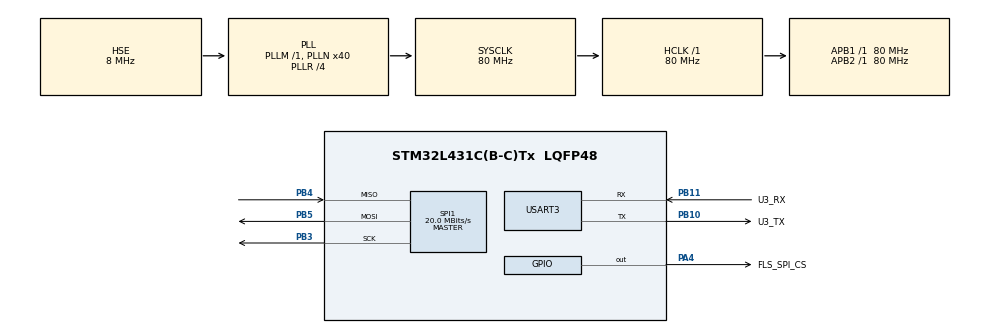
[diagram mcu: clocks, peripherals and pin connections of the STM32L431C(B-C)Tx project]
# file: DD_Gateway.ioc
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Mcu.Family=STM32L4
Mcu.Name=STM32L431C(B-C)Tx
Mcu.Package=LQFP48
NVIC.PriorityGroup=NVIC_PRIORITYGROUP_4
PA4.GPIO_Label=FLS_SPI_CS
PA4.Signal=GPIO_Output
PB10.GPIO_Label=U3_TX
PB10.Mode=Asynchronous
PB10.Signal=USART3_TX
PB11.GPIO_Label=U3_RX
PB11.Mode=Asynchronous
PB11.Signal=USART3_RX
PB3\ (JTDO-TRACESWO).Mode=Full_Duplex_Master
PB3\ (JTDO-TRACESWO).Signal=SPI1_SCK
PB4\ (NJTRST).Mode=Full_Duplex_Master
PB4\ (NJTRST).Signal=SPI1_MISO
PB5.Mode=Full_Duplex_Master
PB5.Signal=SPI1_MOSI
PH0-OSC_IN\ (PH0).Mode=HSE-External-Oscillator
PH0-OSC_IN\ (PH0).Signal=RCC_OSC_IN
PH1-OSC_OUT\ (PH1).Mode=HSE-External-Oscillator
PH1-OSC_OUT\ (PH1).Signal=RCC_OSC_OUT
ProjectManager.HeapSize=0x200
ProjectManager.StackSize=0x400
ProjectManager.TargetToolchain=Makefile
RCC.ADCFreq_Value=32000000
RCC.AHBFreq_Value=80000000
RCC.APB1Freq_Value=80000000
RCC.APB1TimFreq_Value=80000000
RCC.APB2Freq_Value=80000000
RCC.APB2TimFreq_Value=80000000
RCC.CortexFreq_Value=80000000
RCC.HCLKFreq_Value=80000000
RCC.HSE_VALUE=8000000
RCC.HSI48_VALUE=48000000
RCC.HSI_VALUE=16000000
RCC.LSE_VALUE=32768
RCC.MSI_VALUE=4000000
RCC.PLLN=40
RCC.PLLR=RCC_PLLR_DIV4
RCC.PLLSourceVirtual=RCC_PLLSOURCE_HSE
RCC.SYSCLKFreq_VALUE=80000000
RCC.SYSCLKSource=RCC_SYSCLKSOURCE_PLLCLK
RCC.VCOOutputFreq_Value=320000000
SPI1.BaudRatePrescaler=SPI_BAUDRATEPRESCALER_4
SPI1.CalculateBaudRate=20.0 MBits/s
SPI1.DataSize=SPI_DATASIZE_8BIT
SPI1.Direction=SPI_DIRECTION_2LINES
SPI1.Mode=SPI_MODE_MASTER
SPI1.VirtualType=VM_MASTER
USART3.VirtualMode-Asynchronous=VM_ASYNC
board=custom

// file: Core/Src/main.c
/* USER CODE BEGIN Header */
/**
  ******************************************************************************
  * @file           : main.c
  * @brief          : Main program body
  ******************************************************************************
  * @attention
  *
  * Copyright (c) 2023 STMicroelectronics.
  * All rights reserved.
  *
  * This software is licensed under terms that can be found in the LICENSE file
  * in the root directory of this software component.
  * If no LICENSE file comes with this software, it is provided AS-IS.
  *
  ******************************************************************************
  */
/* USER CODE END Header */
#include "main.h"
#include "spi.h"
#include "usart.h"
#include "gpio.h"

void SystemClock_Config(void);

int main(void)
{

  /* MCU Configuration--------------------------------------------------------*/

  /* Reset of all peripherals, Initializes the Flash interface and the Systick. */
  HAL_Init();

  /* Configure the system clock */
  SystemClock_Config();

  /* Initialize all configured peripherals */
  MX_GPIO_Init();
  MX_USART3_UART_Init();
  MX_SPI1_Init();
  /* USER CODE BEGIN 2 */
  BSP_W25Qx_Init();
  /* USER CODE END 2 */

  /* Infinite loop */
  /* USER CODE BEGIN WHILE */
  static uint8_t cnt = 0x00;
  while (1)
  {

    /* USER CODE END WHILE */

    /* USER CODE BEGIN 3 */
    //uint8_t tx_buff[4] = {0x9f,};
    uint8_t rx_buff[300] = {0xff,};
    uint8_t tx_data = 0;
    HAL_Delay(1000);
    cnt++;
    BSP_W25Qx_Read_ID(rx_buff);
    BSP_W25Qx_Read(rx_buff, 0x001FF000, 256);
    BSP_W25Qx_Erase_Page(0x1FF000);
    for(int i = 0;i < 256; ++i)
    {
      tx_data = cnt + i;
      BSP_W25Qx_Write(&tx_data, 0x001FF000+i, 1);
    }
    printf("MID:%d,ID:%d\r\n",rx_buff[1],(uint16_t)rx_buff[2]<<8 | rx_buff[3]);
  }
  /* USER CODE END 3 */
}

void SystemClock_Config(void)
{
  RCC_OscInitTypeDef RCC_OscInitStruct = {0};
  RCC_ClkInitTypeDef RCC_ClkInitStruct = {0};

  /** Configure the main internal regulator output voltage
  */
  if (HAL_PWREx_ControlVoltageScaling(PWR_REGULATOR_VOLTAGE_SCALE1) != HAL_OK)
  {
    Error_Handler();
  }
  /** Initializes the RCC Oscillators according to the specified parameters
  * in the RCC_OscInitTypeDef structure.
  */
  RCC_OscInitStruct.OscillatorType = RCC_OSCILLATORTYPE_HSE;
  RCC_OscInitStruct.HSEState = RCC_HSE_ON;
  RCC_OscInitStruct.PLL.PLLState = RCC_PLL_ON;
  RCC_OscInitStruct.PLL.PLLSource = RCC_PLLSOURCE_HSE;
  RCC_OscInitStruct.PLL.PLLM = 1;
  RCC_OscInitStruct.PLL.PLLN = 40;
  RCC_OscInitStruct.PLL.PLLP = RCC_PLLP_DIV7;
  RCC_OscInitStruct.PLL.PLLQ = RCC_PLLQ_DIV2;
  RCC_OscInitStruct.PLL.PLLR = RCC_PLLR_DIV4;
  if (HAL_RCC_OscConfig(&RCC_OscInitStruct) != HAL_OK)
  {
    Error_Handler();
  }
  /** Initializes the CPU, AHB and APB buses clocks
  */
  RCC_ClkInitStruct.ClockType = RCC_CLOCKTYPE_HCLK|RCC_CLOCKTYPE_SYSCLK
                              |RCC_CLOCKTYPE_PCLK1|RCC_CLOCKTYPE_PCLK2;
  RCC_ClkInitStruct.SYSCLKSource = RCC_SYSCLKSOURCE_PLLCLK;
  RCC_ClkInitStruct.AHBCLKDivider = RCC_SYSCLK_DIV1;
  RCC_ClkInitStruct.APB1CLKDivider = RCC_HCLK_DIV1;
  RCC_ClkInitStruct.APB2CLKDivider = RCC_HCLK_DIV1;

  if (HAL_RCC_ClockConfig(&RCC_ClkInitStruct, FLASH_LATENCY_4) != HAL_OK)
  {
    Error_Handler();
  }
}

void Error_Handler(void)
{
  __disable_irq();
  while (1)
  {
  }
}
